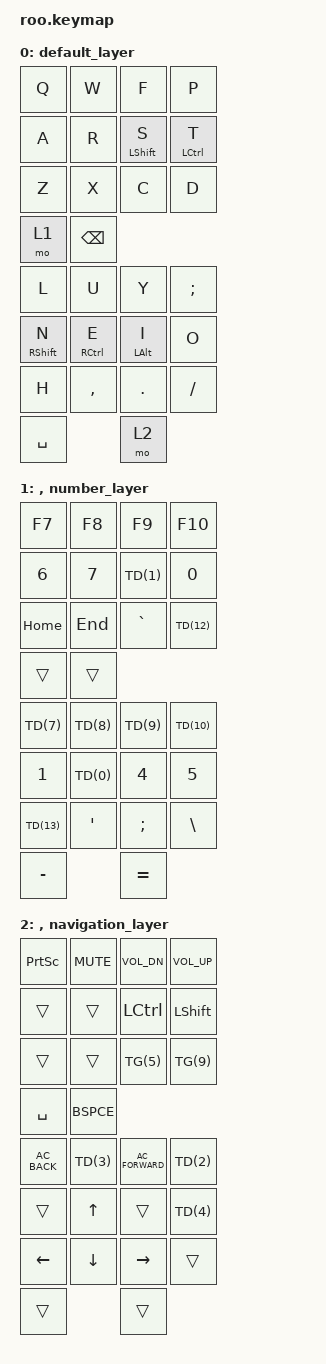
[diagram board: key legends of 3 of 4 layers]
#include <dt-bindings/zmk/mouse.h>

/ {
    keymap {
        compatible = "zmk,keymap";

        default_layer { // Layer 0
            // -------------------------------------
            // | q | w | f | p           l | u | y | m
            // | a | w | s | t           n | e | i | o
            // | z | x | c | d           h | k | j | v
	    //             |num|bk   sp|dir

            bindings = <
                &kp Q &kp W &kp F &kp P 
                &kp A &kp R &mt LSHIFT S &mt LCTRL T
                &kp Z &kp X &kp C &kp D
                &mo 1 &kp BSPC
                &kp L &kp U &kp Y &kp SEMI 
                &mt RSHIFT N &mt RCTRL E &mt LALT I &kp O 
                &kp H &kp COMMA &kp DOT &kp FSLH
                &kp SPACE &mo 2 
            >;
        },
        number_layer {
            // -------------------------------------
            // | F5| F6| F7| F8          F1| F2| F3| F4
            // | 5 | 6 | 7 | 8           1 | 2 | 3 | 4
            // |hm |end| ` | {}          [] | k | j | v
	    //             | g | b   0 | 1

            bindings = <
                &kp F7 &kp F8 &kp F9 &kp F10
                &kp N6 &kp N7 TD(1) &kp N0
                &kp HOME &kp END &kp GRAVE TD(12)
                &trans &trans
                TD(7) TD(8) TD(9) TD(10)
                &kp N1 TD(0) &kp N4 &kp N5 
                TD(13) &kp SQT &kp SEMI &kp BSLH
                &kp MINUS &kp EQUAL
            >;
        },
        navigation_layer {

            bindings = <
                &kp PSCRN &kp C_MUTE &kp C_VOL_DN &kp C_VOL_UP
                &trans &trans &kp LCTRL &kp LSHIFT
                &trans &trans TG(5) TG(9)
                &kp SPACE &kp BSPCE 
                &kp C_AC_BACK TD(3) &kp C_AC_FORWARD TD(2) 
                &trans &kp UP &trans TD(4) 
                &kp LEFT &kp DOWN &kp RIGHT &trans 
                &trans &trans 
            >;
         },
        mouse_layer {

            bindings = <
                &kp Q &kp W &kp E &kp R 
                &kp A &kp S &mt LCTRL D &mt LSHIFT F 
                &kp Z &kp X &kp C &kp V 
                &trans &trans

                &kp C_AC_BACK TD(3) &kp C_AC_BACK TD(2) &trans 
                M0 &kp MS_U M1 &kp WH_U
                &kp MS_L &kp MS_D &kp MS_R &kp WH_D
                &kp BTN1 TD(5)
            >;
        }
    };
 };

 
 

